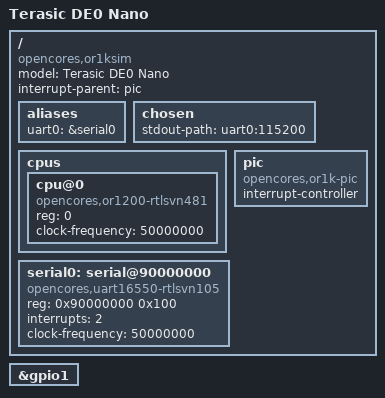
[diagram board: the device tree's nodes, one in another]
// SPDX-License-Identifier: GPL-2.0

/dts-v1/;

#include "de0-nano-common.dtsi"

/ {
	model = "Terasic DE0 Nano";
	compatible = "opencores,or1ksim";
	#address-cells = <1>;
	#size-cells = <1>;
	interrupt-parent = <&pic>;

	aliases {
		uart0 = &serial0;
	};

	chosen {
		stdout-path = "uart0:115200";
	};

	cpus {
		#address-cells = <1>;
		#size-cells = <0>;

		cpu@0 {
			compatible = "opencores,or1200-rtlsvn481";
			reg = <0>;
			clock-frequency = <50000000>;
		};
	};

	/*
	 * OR1K PIC is built into CPU and accessed via special purpose
	 * registers.  It is not addressable and, hence, has no 'reg'
	 * property.
	 */
	pic: pic {
		compatible = "opencores,or1k-pic";
		#interrupt-cells = <1>;
		interrupt-controller;
	};

	serial0: serial@90000000 {
		compatible = "opencores,uart16550-rtlsvn105", "ns16550a";
		reg = <0x90000000 0x100>;
		interrupts = <2>;
		clock-frequency = <50000000>;
	};
};

&gpio1 {
	status = "okay";
};
